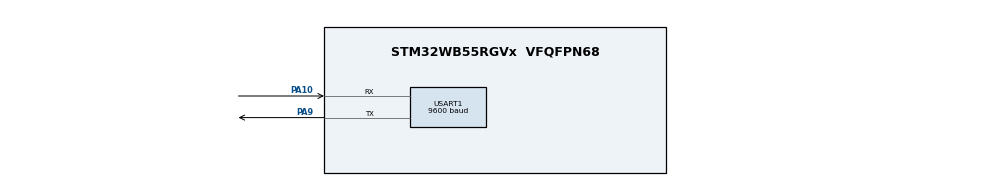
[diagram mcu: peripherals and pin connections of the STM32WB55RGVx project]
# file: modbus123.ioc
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Dma.Request0=USART1_RX
Dma.USART1_RX.0.Direction=DMA_PERIPH_TO_MEMORY
Dma.USART1_RX.0.EventEnable=DISABLE
Dma.USART1_RX.0.Instance=DMA1_Channel1
Dma.USART1_RX.0.MemDataAlignment=DMA_MDATAALIGN_BYTE
Dma.USART1_RX.0.MemInc=DMA_MINC_ENABLE
Dma.USART1_RX.0.Mode=DMA_NORMAL
Dma.USART1_RX.0.PeriphDataAlignment=DMA_PDATAALIGN_BYTE
Dma.USART1_RX.0.PeriphInc=DMA_PINC_DISABLE
Dma.USART1_RX.0.Polarity=HAL_DMAMUX_REQ_GEN_RISING
Dma.USART1_RX.0.Priority=DMA_PRIORITY_HIGH
Dma.USART1_RX.0.RequestNumber=1
Dma.USART1_RX.0.SignalID=NONE
Dma.USART1_RX.0.SyncEnable=DISABLE
Dma.USART1_RX.0.SyncPolarity=HAL_DMAMUX_SYNC_NO_EVENT
Dma.USART1_RX.0.SyncRequestNumber=1
Dma.USART1_RX.0.SyncSignalID=NONE
Mcu.Family=STM32WB
Mcu.Name=STM32WB55RGVx
Mcu.Package=VFQFPN68
NVIC.DMA1_Channel1_IRQn=true\:0\:0\:false\:false\:true\:false\:true\:true
NVIC.PriorityGroup=NVIC_PRIORITYGROUP_4
NVIC.USART1_IRQn=true\:0\:0\:false\:false\:true\:true\:true\:true
PA10.Mode=Asynchronous
PA10.Signal=USART1_RX
PA13.Mode=Serial_Wire
PA13.Signal=SYS_JTMS-SWDIO
PA14.Mode=Serial_Wire
PA14.Signal=SYS_JTCK-SWCLK
PA9.Mode=Asynchronous
PA9.Signal=USART1_TX
ProjectManager.HeapSize=0x200
ProjectManager.StackSize=0x400
ProjectManager.TargetToolchain=STM32CubeIDE
RCC.APB3Freq_Value=16000000
RCC.HSE_VALUE=8000000
RCC.HSI48_VALUE=48000000
RCC.HSI_VALUE=16000000
RCC.LSE_VALUE=32768
RCC.VCOOutputFreq_Value=32000000
USART1.BaudRate=9600
USART1.VirtualMode-Asynchronous=VM_ASYNC
VP_MEMORYMAP_VS_MEMORYMAP.Mode=CurAppReg
board=custom

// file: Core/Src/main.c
/* USER CODE BEGIN Header */
/**
  ******************************************************************************
  * @file           : main.c
  * @brief          : Main program body
  ******************************************************************************
  * @attention
  *
  * Copyright (c) 2026 STMicroelectronics.
  * All rights reserved.
  *
  * This software is licensed under terms that can be found in the LICENSE file
  * in the root directory of this software component.
  * If no LICENSE file comes with this software, it is provided AS-IS.
  *
  ******************************************************************************
  */
/* USER CODE END Header */
#include "main.h"
#include "dma.h"
#include "usart.h"
#include "gpio.h"

/* USER CODE BEGIN Includes */
#include <string.h>
#include "modbus_rtu.h"
#include "modbus_crc.h"
#include "register_map.h"
#include "bms_state.h"
/* USER CODE END Includes */

/* USER CODE BEGIN PV */
uint8_t rxBuffer[256];

/* Modbus handle'ları */
static BMS_State_t    gBmsState;
static Modbus_Handle_t hModbus;
/* USER CODE END PV */

void SystemClock_Config(void);
void PeriphCommonClock_Config(void);

int main(void)
{

  /* MCU Configuration--------------------------------------------------------*/

  /* Reset of all peripherals, Initializes the Flash interface and the Systick. */
  HAL_Init();

  /* Configure the system clock */
  SystemClock_Config();

  /* Configure the peripherals common clocks */
  PeriphCommonClock_Config();

  /* Initialize all configured peripherals */
  MX_GPIO_Init();
  MX_DMA_Init();
  MX_USART1_UART_Init();
  /* USER CODE BEGIN 2 */

  /* ── Modbus Modüllerini Başlat ──────────────────────────────────── */
  BMS_State_Init(&gBmsState);
  RegMap_Init(&gBmsState);
  Modbus_Init(&hModbus, &gBmsState, gBmsState.slave_address);

  /* ── DMA ile UART alımını başlat ────────────────────────────────── */
  HAL_UARTEx_ReceiveToIdle_DMA(&huart1,
                               rxBuffer,
                               sizeof(rxBuffer));

  __HAL_DMA_DISABLE_IT(huart1.hdmarx,
                       DMA_IT_HT);
  /* USER CODE END 2 */

  /* Infinite loop */
  while (1)
  {

  }
}

void SystemClock_Config(void)
{
  RCC_OscInitTypeDef RCC_OscInitStruct = {0};
  RCC_ClkInitTypeDef RCC_ClkInitStruct = {0};

  /** Configure the main internal regulator output voltage
  */
  __HAL_PWR_VOLTAGESCALING_CONFIG(PWR_REGULATOR_VOLTAGE_SCALE1);

  /** Initializes the RCC Oscillators according to the specified parameters
  * in the RCC_OscInitTypeDef structure.
  */
  RCC_OscInitStruct.OscillatorType = RCC_OSCILLATORTYPE_HSI|RCC_OSCILLATORTYPE_MSI;
  RCC_OscInitStruct.HSIState = RCC_HSI_ON;
  RCC_OscInitStruct.MSIState = RCC_MSI_ON;
  RCC_OscInitStruct.HSICalibrationValue = RCC_HSICALIBRATION_DEFAULT;
  RCC_OscInitStruct.MSICalibrationValue = RCC_MSICALIBRATION_DEFAULT;
  RCC_OscInitStruct.MSIClockRange = RCC_MSIRANGE_6;
  RCC_OscInitStruct.PLL.PLLState = RCC_PLL_NONE;
  if (HAL_RCC_OscConfig(&RCC_OscInitStruct) != HAL_OK)
  {
    Error_Handler();
  }

  /** Configure the SYSCLKSource, HCLK, PCLK1 and PCLK2 clocks dividers
  */
  RCC_ClkInitStruct.ClockType = RCC_CLOCKTYPE_HCLK4|RCC_CLOCKTYPE_HCLK2
                              |RCC_CLOCKTYPE_HCLK|RCC_CLOCKTYPE_SYSCLK
                              |RCC_CLOCKTYPE_PCLK1|RCC_CLOCKTYPE_PCLK2;
  RCC_ClkInitStruct.SYSCLKSource = RCC_SYSCLKSOURCE_MSI;
  RCC_ClkInitStruct.AHBCLKDivider = RCC_SYSCLK_DIV1;
  RCC_ClkInitStruct.APB1CLKDivider = RCC_HCLK_DIV1;
  RCC_ClkInitStruct.APB2CLKDivider = RCC_HCLK_DIV1;
  RCC_ClkInitStruct.AHBCLK2Divider = RCC_SYSCLK_DIV1;
  RCC_ClkInitStruct.AHBCLK4Divider = RCC_SYSCLK_DIV1;

  if (HAL_RCC_ClockConfig(&RCC_ClkInitStruct, FLASH_LATENCY_0) != HAL_OK)
  {
    Error_Handler();
  }
}

void PeriphCommonClock_Config(void)
{
  RCC_PeriphCLKInitTypeDef PeriphClkInitStruct = {0};

  /** Initializes the peripherals clock
  */
  PeriphClkInitStruct.PeriphClockSelection = RCC_PERIPHCLK_SMPS;
  PeriphClkInitStruct.SmpsClockSelection = RCC_SMPSCLKSOURCE_HSI;
  PeriphClkInitStruct.SmpsDivSelection = RCC_SMPSCLKDIV_RANGE1;

  if (HAL_RCCEx_PeriphCLKConfig(&PeriphClkInitStruct) != HAL_OK)
  {
    Error_Handler();
  }
}

/* USER CODE BEGIN 4 */

/**
 * @brief  UART ReceiveToIdle DMA Callback — Modbus frame işleme
 *
 * DMA + IDLE line detection ile frame otomatik alınır.
 * Frame gelince:
 *   1) Modbus_ProcessFrame() çağrılır (CRC check, parse, handler)
 *   2) Yanıt varsa UART_Transmit ile gönderilir
 *   3) DMA tekrar başlatılır (sonraki frame için)
 */
void HAL_UARTEx_RxEventCallback(UART_HandleTypeDef *huart,
                                uint16_t Size)
{
    if (huart->Instance == USART1)
    {
        /* ── Modbus frame'i işle ──────────────────────────────────── */
        if (Modbus_ProcessFrame(&hModbus, rxBuffer, Size))
        {
            /* Yanıt oluşturuldu → gönder */
            HAL_UART_Transmit(&huart1,
                              hModbus.responseBuffer,
                              hModbus.responseLength,
                              HAL_MAX_DELAY);
        }

        /* ── DMA'yı tekrar başlat (sonraki frame için) ────────────── */
        HAL_UARTEx_ReceiveToIdle_DMA(&huart1,
                                     rxBuffer,
                                     sizeof(rxBuffer));

        __HAL_DMA_DISABLE_IT(huart1.hdmarx,
                             DMA_IT_HT);
    }
}
/* USER CODE END 4 */

void Error_Handler(void)
{
  __disable_irq();
  while (1)
  {
  }
}
